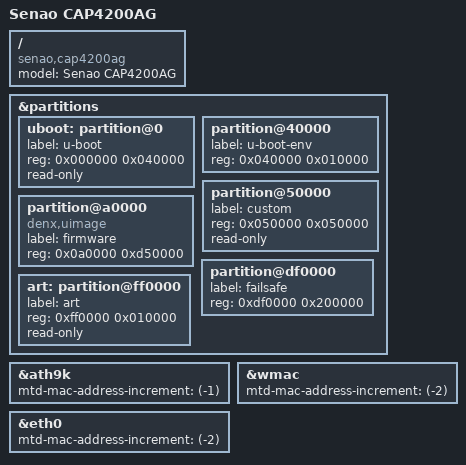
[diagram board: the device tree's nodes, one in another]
// SPDX-License-Identifier: GPL-2.0-or-later OR MIT
/dts-v1/;

#include "ar9344_senao_cap4200ag.dtsi"

/ {
	model = "Senao CAP4200AG";
	compatible = "senao,cap4200ag", "qca,ar9344";
};

&partitions {
	uboot: partition@0 {
		label = "u-boot";
		reg = <0x000000 0x040000>;
		read-only;
	};

	partition@40000 {
		label = "u-boot-env";
		reg = <0x040000 0x010000>;
	};

	partition@50000 {
		label = "custom";
		reg = <0x050000 0x050000>;
		read-only;
	};

	partition@a0000 {
		compatible = "denx,uimage";
		label = "firmware";
		reg = <0x0a0000 0xd50000>;
	};

	partition@df0000 {
		label = "failsafe";
		reg = <0xdf0000 0x200000>;
	};

	art: partition@ff0000 {
		label = "art";
		reg = <0xff0000 0x010000>;
		read-only;
	};
};

&ath9k {
	mtd-mac-address-increment = <(-1)>;
};

&wmac {
	mtd-mac-address-increment = <(-2)>;
};

&eth0 {
	mtd-mac-address-increment = <(-2)>;
};
